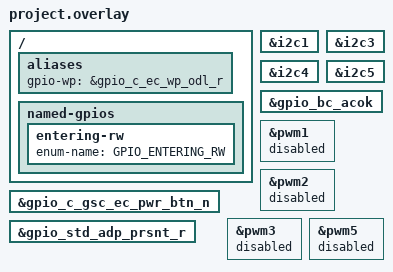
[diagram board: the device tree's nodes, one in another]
/* Copyright 2025 The ChromiumOS Authors
 * Use of this source code is governed by a BSD-style license that can be
 * found in the LICENSE file.
 */

/* ocelot program common DTS includes */

#include <cros/integrated_fwid.dtsi>

/* ocelot_ite project DTS includes */

#include "generated.dtsi"

/*
 * Map I2C buses to common names
 */

i2c_port_pd1: &i2c1 {
};

i2c_port_pd2: &i2c3 {
};

i2c_port_charger: &i2c4 {
};

i2c_port_ish: &i2c5 {
};

/* Map ITE specific GPIOs to the names required by the rvp interrupts. */
bc_acok: &gpio_bc_acok {};
pwrbtn: &gpio_c_gsc_ec_pwr_btn_n{};
std_adp_prsnt: &gpio_std_adp_prsnt_r {};

#include "../rvp_battery.dtsi"
#include "../rvp_i2c.dtsi"
#include "../rvp_interrupts.dtsi"

/* ocelot_ite overrides follow... */
/ {
	aliases {
		gpio-wp = &gpio_c_ec_wp_odl_r;
	};

	named-gpios {
		/* unimplemented GPIOs */
		entering-rw {
			enum-name = "GPIO_ENTERING_RW";
		};
	};
};

/* Disable nodes for features not yet enabled. */
/delete-node/ &{/named-adc-channels};
/delete-node/ &int_power_button;
/delete-node/ &int_dc_jack_present;

&pwm1 {
	status = "disabled";
};
&pwm2 {
	status = "disabled";
};
&pwm3 {
	status = "disabled";
};
&pwm5 {
	status = "disabled";
};
